# MM32F3270 register map
File version: 3.01
CPU: CM3 r2p1, selectable endian, MPU, no FPU, 3 interrupt priority bits
Registers are 32-bit, read-write, reset 0x0 unless marked. A register's access mark holds for its fields unless they carry their own. Offsets are from the block's base; [hi:lo] are bit positions; lines under a group give offsets from that group; {n}, {i} and the like mark numbered series; 'fields as' and 'values as' point back to an identical list.

## ADC1 — Analog to digital converter 1
Base 0x40012400
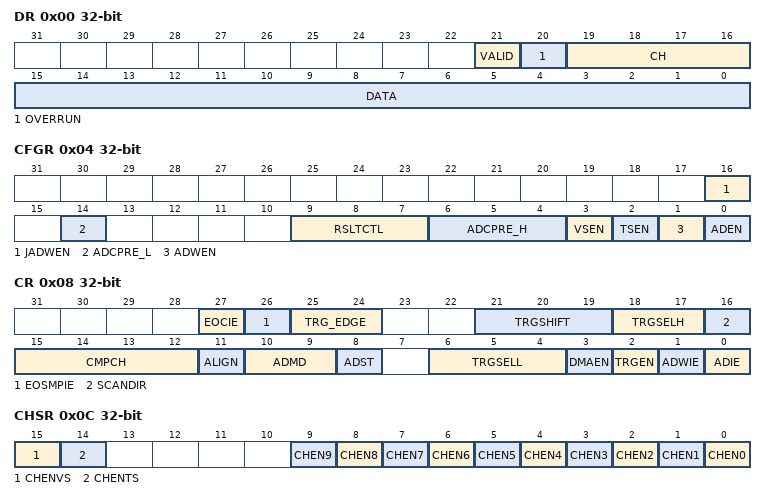
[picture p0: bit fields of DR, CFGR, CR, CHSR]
0x00 DR ro — Data register
  [21] VALID — Valid flag
  [20] OVERRUN — Overrun flag
  [19:16] CH — ADC current channel Transfer data
  [15:0] DATA — Transfer data
0x04 CFGR — Configure register
  [16] JADWEN — Inject ADC conversion window comparison enable
  [14] ADCPRE_L — ADC prescaler_l
  [9:7] RSLTCTL — Resolution
  [6:4] ADCPRE_H — ADC prescaler_h
  [3] VSEN — Voltage Sensor enable
  [2] TSEN — Temperature sensor enable
  [1] ADWEN — ADC window comparison enable
  [0] ADEN — ADC enable
0x08 CR — Control register
  [27] EOCIE — ADC end of conversion interrupt enable
  [26] EOSMPIE — ADC end sampling flag interrupt enable
  [25:24] TRG_EDGE — Trigger edge selection
  [21:19] TRGSHIFT — External trigger shift sample
  [18:17] TRGSELH — External trigger selection_h
  [16] SCANDIR — ADC scan direction
  [15:12] CMPCH — Window comparison channel selection
  [11] ALIGN — Data alignment
  [10:9] ADMD — ADC mode
  [8] ADST — ADC start
  [6:4] TRGSELL — External trigger selection_l
  [3] DMAEN — Direct memory access enable
  [2] TRGEN — External trigger enable
  [1] ADWIE — ADC window comparator interrupt enable
  [0] ADIE — ADC interrupt enable
0x0C CHSR — Channel select register
  [15] CHENVS — Voltage Sensor enable
  [14] CHENTS — emperature Sensor enable
  [n] CHEN{n} (n=0..9) — Analog input channel {n} enable
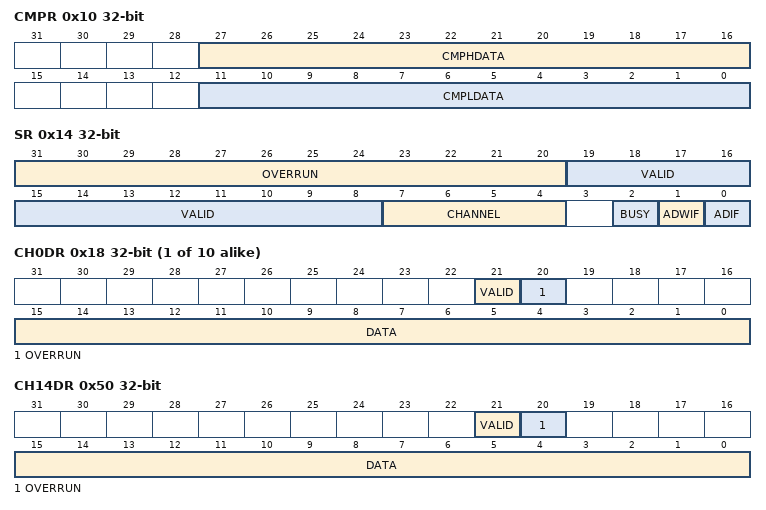
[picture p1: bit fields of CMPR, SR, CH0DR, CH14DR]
0x10 CMPR — Compare register
  [27:16] CMPHDATA — ADC 12bit window compare UP LEVEL DATA
  [11:0] CMPLDATA — ADC 12bit window compare DOWN LEVEL DATA
0x14 SR — Status register
  [31:20] OVERRUN ro — Overrun flag
  [19:8] VALID ro — Valid flag
  [7:4] CHANNEL ro — Current conversion channel
  [2] BUSY ro
  [1] ADWIF write-1-clears — ADC window comparator interrupt flag
  [0] ADIF write-1-clears — ADC interrupt flag
{0x18+4i} CH{i}DR ro (i=0..9) — Channel {i} data register
  [21] VALID — Valid flag
  [20] OVERRUN — Overrun flag
  [15:0] DATA — Transfer data
0x50 CH14DR ro — Channel 14 data register
  fields as CH0DR
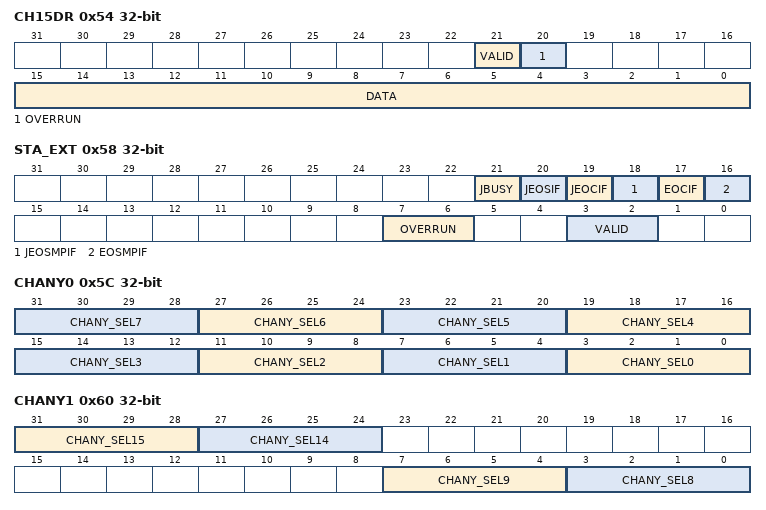
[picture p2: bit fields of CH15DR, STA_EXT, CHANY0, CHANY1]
0x54 CH15DR ro — Channel 15 data register
  fields as CH0DR
0x58 STA_EXT ro — Extend state register
  [21] JBUSY — Injection mode
  [20] JEOSIF — Injected channel end of sequential conversion interrupt flag
  [19] JEOCIF — Injected channel end of conversion interrupt flag
  [18] JEOSMPIF — Injected channel end of sampling interrupt flag
  [17] EOCIF — End of conversion interrupt flag
  [16] EOSMPIF — End of sampling interrupt flag
  [7:6] OVERRUN — Channel data Overrun flag
  [3:2] VALID — Channel data Valid flag
0x5C CHANY0 — Arbitrary channel channel selection register 0
  [4n+3:4n] CHANY_SEL{n} (n=0..7) — Can be configured as any channel from ch0 to 9, 14 to 15.
0x60 CHANY1 — Arbitrary channel channel selection register 1
  [31:28] CHANY_SEL15 — Can be configured as any channel from ch0 to 9, 14 to 15.
  [27:24] CHANY_SEL14 — Can be configured as any channel from ch0 to 9, 14 to 15.
  [7:4] CHANY_SEL9 — Can be configured as any channel from ch0 to 9, 14 to 15.
  [3:0] CHANY_SEL8 — Can be configured as any channel from ch0 to 9, 14 to 15.
0x64 ANY_CFG — Arbitrary channel configuration register
  [3:0] CHANY_NUM — channel number configuration
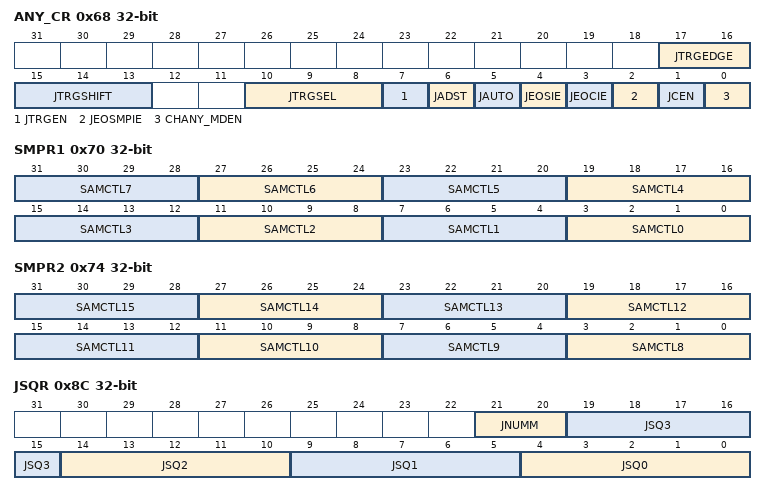
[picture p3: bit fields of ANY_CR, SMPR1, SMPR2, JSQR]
0x68 ANY_CR — Arbitrary channel control register
  [17:16] JTRGEDGE — Injection mode trigger edge selection
  [15:13] JTRGSHIFT — Injection mode external trigger delay sampling
  [10:8] JTRGSEL — External event select for in-jected group
  [7] JTRGEN — External trigger conversion mode for injected channels
  [6] JADST — Start conversion of injected channels
  [5] JAUTO — Automatic Injected group conversion
  [4] JEOSIE — Interrupt enable the end of sequence conversion for injected channel
  [3] JEOCIE — Interrupt enable the end of conversion for injected channel
  [2] JEOSMPIE — Interrupt enable the end of sequence conversion for injected channel
  [1] JCEN — Injected channel enable
  [0] CHANY_MDEN — Any channel configuration mode enable bit
0x70 SMPR1 — Any channel configuration register 1
  [4n+3:4n] SAMCTL{n} (n=0..7) — Channel {n} Sample time selection
0x74 SMPR2 — Any channel configuration register 2
  [4n-29:4n-32] SAMCTL{n} (n=8..15) — Channel {n} Sample time selection
{0x7C+4i} JOFR{i} (i=0..3) — Injection channe {i} data compensation register
  [11:0] JOFR — The A_D conversion result of injection channel {i} is compensated After subtracting the compensation value, the conversion result is obtained and stored in jdata
0x8C JSQR — Injection sequence register
  [21:20] JNUMM — Injection channel sequence length
  [19:15] JSQ3 — The fourth conversion channel number in the injection sequence
  [14:10] JSQ2 — The third conversion channel number in the injection sequence
  [9:5] JSQ1 — The second conversion channel in the injection sequence
  [4:0] JSQ0 — The first conversion channel in the injection sequence
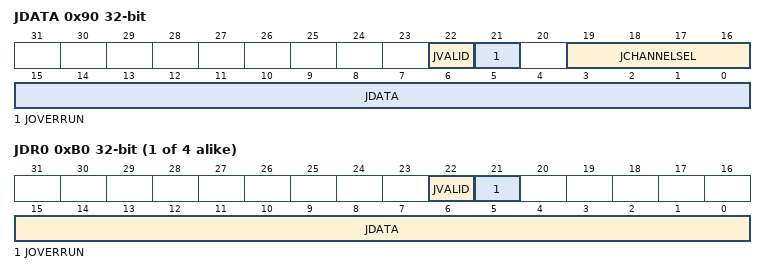
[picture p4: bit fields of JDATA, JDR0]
0x90 JDATA ro — Injection data register
  [22] JVALID — Valid flag
  [21] JOVERRUN — Overrun flag
  [19:16] JCHANNELSEL — Channel selection
  [15:0] JDATA — Transfer data
{0xB0+4i} JDR{i} ro (i=0..3) — Injection data register
  [22] JVALID — Valid flag
  [21] JOVERRUN — Overrun flag
  [15:0] JDATA — Transfer data

## ADC2 — Analog to digital converter 2
Base 0x40012800
Same registers: ADC3 0x40014C00
Registers as ADC1; these are added or differ:
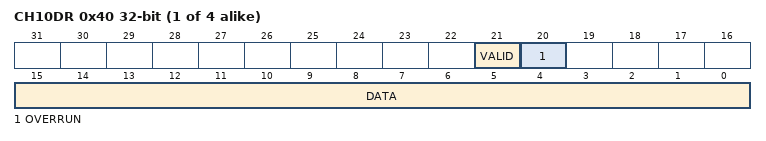
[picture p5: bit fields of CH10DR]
{0x18+4i} CH{i}DR ro (i=10..13) — Channel {i} data register
  [21] VALID — Valid flag
  [20] OVERRUN — Overrun flag
  [15:0] DATA — Transfer data
